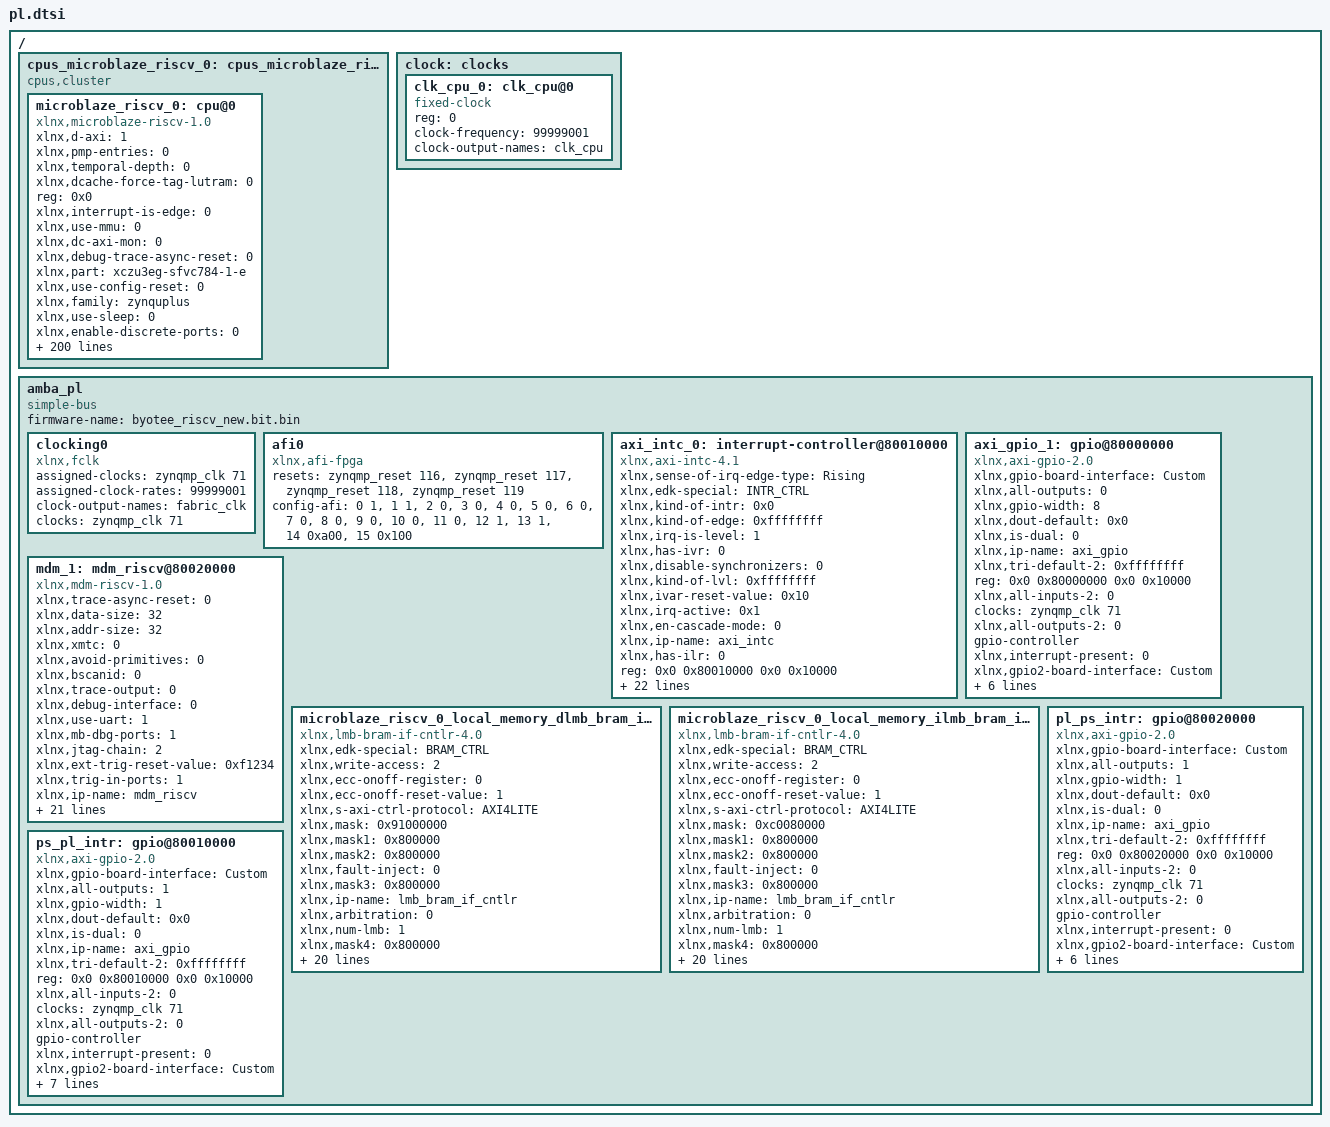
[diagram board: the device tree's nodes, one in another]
/ {
	cpus_microblaze_riscv_0: cpus_microblaze_riscv@0 {
		#cpu-mask-cells = <1>;
		compatible = "cpus,cluster";
		#address-cells = <1>;
		#size-cells = <0>;
		microblaze_riscv_0: cpu@0 {
			xlnx,d-axi = <1>;
			xlnx,pmp-entries = <0>;
			xlnx,temporal-depth = <0>;
			xlnx,dcache-force-tag-lutram = <0>;
			reg = <0x0>;
			xlnx,interrupt-is-edge = <0>;
			xlnx,use-mmu = <0>;
			xlnx,dc-axi-mon = <0>;
			xlnx,debug-trace-async-reset = <0>;
			xlnx,part = "xczu3eg-sfvc784-1-e";
			xlnx,use-config-reset = <0>;
			xlnx,family = "zynquplus";
			xlnx,use-sleep = <0>;
			xlnx,enable-discrete-ports = <0>;
			xlnx,d-lmb = <1>;
			xlnx,debug-interface = <0>;
			xlnx,use-ext-brk = <0>;
			xlnx,debug-enabled = <1>;
			xlnx,daddr-size = <32>;
			xlnx,use-extended-fsl-instr = <0>;
			xlnx,branch-target-cache-size = <0>;
			bus-handle = <&amba_pl>;
			xlnx,pmp-addr0 = <0x0>;
			xlnx,pmp-addr1 = <0x0>;
			xlnx,pmp-addr2 = <0x0>;
			xlnx,pmp-addr3 = <0x0>;
			xlnx,pmp-addr4 = <0x0>;
			xlnx,edk-special = "microblaze_riscv";
			xlnx,pmp-addr5 = <0x0>;
			xlnx,use-dcache = <0>;
			xlnx,use-muldiv = <0>;
			xlnx,pmp-addr6 = <0x0>;
			xlnx,use-axi-dp-ext-addr = <0>;
			xlnx,pmp-addr7 = <0x0>;
			xlnx,pmp-addr8 = <0x0>;
			xlnx,pmp-addr9 = <0x0>;
			xlnx,i-axi = <1>;
			xlnx,icache-streams = <0>;
			xlnx,num-sync-ff-dbg-clk = <1>;
			xlnx,icache-byte-size = <16384>;
			xlnx,pmp-addr10 = <0x0>;
			d-cache-size = <16384>;
			xlnx,pmp-addr11 = <0x0>;
			xlnx,pmp-addr12 = <0x0>;
			xlnx,pmp-addr13 = <0x0>;
			xlnx,pmp-addr14 = <0x0>;
			xlnx,pmp-addr15 = <0x0>;
			xlnx,avoid-primitives = <0>;
			xlnx,pmp-addr16 = <0x0>;
			xlnx,pmp-addr17 = <0x0>;
			xlnx,pmp-addr18 = <0x0>;
			xlnx,pdaddr-size = <32>;
			xlnx,pmp-addr19 = <0x0>;
			xlnx,pmp-addr20 = <0x0>;
			xlnx,pmp-addr21 = <0x0>;
			xlnx,i-lmb = <1>;
			xlnx,pmp-addr22 = <0x0>;
			xlnx,lmb-data-size = <32>;
			xlnx,lockstep-select = <0>;
			xlnx,pmp-addr23 = <0x0>;
			timebase-frequency = <99999001>;
			xlnx,pmp-addr24 = <0x0>;
			xlnx,dcache-data-width = <0>;
			xlnx,icache-force-tag-lutram = <0>;
			xlnx,pmp-addr25 = <0x0>;
			xlnx,pmp-addr26 = <0x0>;
			xlnx,use-branch-target-cache = <0>;
			xlnx,pmp-addr27 = <0x0>;
			xlnx,number-of-pc-brk = <1>;
			xlnx,pmp-addr28 = <0x0>;
			xlnx,imprecise-exceptions = <0>;
			xlnx,pmp-addr29 = <0x0>;
			xlnx,pmp-addr30 = <0x0>;
			xlnx,pmp-addr31 = <0x0>;
			xlnx,pmp-addr32 = <0x0>;
			model = "microblaze_riscv,1.0";
			xlnx,pmp-addr33 = <0x0>;
			xlnx,pmp-addr34 = <0x0>;
			xlnx,pmp-addr35 = <0x0>;
			xlnx,pmp-addr36 = <0x0>;
			d-cache-highaddr = <0xffffffff>;
			xlnx,optimization = <0>;
			xlnx,pmp-addr37 = <0x0>;
			xlnx,pmp-addr38 = <0x0>;
			xlnx,pmp-addr39 = <0x0>;
			xlnx,pmp-addr40 = <0x0>;
			xlnx,pmp-addr41 = <0x0>;
			xlnx,d-lmb-mon = <0>;
			xlnx,pmp-addr42 = <0x0>;
			xlnx,pmp-addr43 = <0x0>;
			xlnx,pmp-addr44 = <0x0>;
			xlnx,pmp-addr45 = <0x0>;
			xlnx,pmp-addr46 = <0x0>;
			xlnx,pmp-addr47 = <0x0>;
			xlnx,pmp-addr48 = <0x0>;
			xlnx,fault-tolerant = <0>;
			xlnx,pmp-addr49 = <0x0>;
			xlnx,pmp-addr50 = <0x0>;
			xlnx,pmp-addr51 = <0x0>;
			xlnx,pmp-enhancements = <0>;
			d-cache-line-size = <16>;
			xlnx,mmu-privileged-instr = <0>;
			xlnx,pmp-addr52 = <0x0>;
			clock-frequency = <99999001>;
			xlnx,pmp-addr53 = <0x0>;
			xlnx,pmp-addr54 = <0x0>;
			xlnx,pmp-addr55 = <0x0>;
			xlnx,i-lmb-protocol = <0>;
			xlnx,pmp-addr56 = <0x0>;
			xlnx,pmp-addr57 = <0x0>;
			xlnx,dp-axi-mon = <0>;
			xlnx,pmp-addr58 = <0x0>;
			xlnx,pmp-addr59 = <0x0>;
			xlnx,pmp-addr60 = <0x0>;
			xlnx,pmp-addr61 = <0x0>;
			xlnx,pmp-addr62 = <0x0>;
			xlnx,pmp-addr63 = <0x0>;
			xlnx,debug-external-trace = <0>;
			xlnx,addr-size = <32>;
			xlnx,debug-event-counters = <0>;
			xlnx,edk-iptype = "PROCESSOR";
			xlnx,debug-latency-counters = <0>;
			xlnx,interconnect = <2>;
			xlnx,edge-is-positive = <1>;
			xlnx,use-icache = <0>;
			xlnx,async-wakeup = <3>;
			xlnx,s-axi = <0>;
			xlnx,use-ext-nm-brk = <0>;
			xlnx,ic-axi-mon = <0>;
			xlnx,archid = <0x1>;
			xlnx,num-sync-ff-clk-irq = <1>;
			xlnx,freq = <99999001>;
			xlnx,lockstep-master = <0>;
			xlnx,pmp-cfg0 = <0x0>;
			xlnx,pmp-cfg1 = <0x0>;
			xlnx,iaddr-size = <32>;
			xlnx,interrupt-mon = <0>;
			xlnx,pmp-cfg2 = <0x0>;
			xlnx,number-of-wr-addr-brk = <0>;
			xlnx,pmp-cfg3 = <0x0>;
			xlnx,pmp-cfg4 = <0x0>;
			xlnx,use-interrupt = <1>;
			xlnx,pmp-cfg5 = <0x0>;
			xlnx,async-interrupt = <1>;
			xlnx,pc-width = <32>;
			xlnx,pmp-cfg6 = <0x0>;
			xlnx,icache-victims = <0>;
			xlnx,pmp-cfg7 = <0x0>;
			xlnx,pmp-cfg8 = <0x0>;
			xlnx,pmp-cfg9 = <0x0>;
			xlnx,use-bitman-a = <0>;
			xlnx,use-bitman-b = <0>;
			xlnx,use-bitman-c = <0>;
			xlnx,i-lmb-mon = <0>;
			xlnx,dcache-byte-size = <16384>;
			xlnx,data-size = <32>;
			compatible = "xlnx,microblaze-riscv-1.0" , "xlnx,microblaze_riscv";
			xlnx,pmp-debug-inhibit = <0x0>;
			xlnx,fsl-exception = <0>;
			xlnx,dcache-use-writeback = <0>;
			device_type = "cpu";
			xlnx,impid = <0x1>;
			xlnx,use-bitman-s = <0>;
			xlnx,base-vectors = <0x90080000>;
			xlnx,icache-line-len = <4>;
			xlnx,use-barrel = <1>;
			xlnx,misaligned-exceptions = <1>;
			xlnx,piaddr-size = <32>;
			xlnx,use-bitman = <0>;
			xlnx,dcache-line-len = <4>;
			xlnx,num-sync-ff-clk = <2>;
			xlnx,memory-ip-list = "psu_ddr_0_memory" , "psu_ddr_0_memory" , "psu_ocm_ram_0_memory" , "psu_ocm_ram_0_memory" , "psu_r5_1_btcm_global_memory" , "psu_r5_1_btcm_global_memory" , "psu_r5_1_atcm_global_memory" , "psu_r5_1_atcm_global_memory" , "psu_r5_0_btcm_global_memory" , "psu_r5_0_btcm_global_memory" , "psu_r5_0_atcm_global_memory" , "psu_r5_0_atcm_global_memory";
			xlnx,number-of-rd-addr-brk = <0>;
			xlnx,lockstep-slave = <0>;
			xlnx,use-counters = <1>;
			interrupt-handle = <&axi_intc_0>;
			xlnx,pmp-cfg10 = <0x0>;
			xlnx,pmp-cfg11 = <0x0>;
			xlnx,debug-profile-size = <0>;
			xlnx,pmp-cfg12 = <0x0>;
			xlnx,pmp-cfg13 = <0x0>;
			xlnx,pmp-cfg14 = <0x0>;
			xlnx,pmp-cfg15 = <0x0>;
			xlnx,debug-counter-width = <64>;
			xlnx,icache-data-width = <0>;
			xlnx,ip-name = "microblaze_riscv";
			xlnx,ip-axi-mon = <0>;
			xlnx,d-lmb-protocol = <0>;
			xlnx,trace = <0>;
			xlnx,ill-instr-exception = <2>;
			xlnx,debug-trace-size = <0>;
			xlnx,pmp-granularity = <2>;
			xlnx,num-sync-ff-dbg-trace-clk = <2>;
			xlnx,ecc-use-ce-exception = <0>;
			xlnx,num-sync-ff-clk-debug = <2>;
			xlnx,use-atomic = <0>;
			xlnx,g-template-list = <0>;
			xlnx,hartid = <0x0>;
			xlnx,use-fpu = <0>;
			xlnx,use-non-secure = <0>;
			d-cache-baseaddr = <0x80000000>;
			xlnx,use-compression = <0>;
			xlnx,instr-size = <32>;
			xlnx,fsl-links = <0>;
			xlnx,dcache-victims = <0>;
			xlnx,pmp-read-only = <0x0>;
		};
	};
	clock: clocks {
		#address-cells = <1>;
		#size-cells = <0>;
		clk_cpu_0: clk_cpu@0 {
			compatible = "fixed-clock";
			reg = <0>;
			clock-frequency = <99999001>;
			clock-output-names = "clk_cpu";
			#clock-cells = <0>;
		};
	};
	amba_pl: amba_pl {
		ranges;
		compatible = "simple-bus";
		#address-cells = <2>;
		#size-cells = <2>;
		firmware-name = "byotee_riscv_new.bit.bin";
		clocking0: clocking0 {
			compatible = "xlnx,fclk";
			status = "okay";
			assigned-clocks = <&zynqmp_clk 71>;
			assigned-clock-rates = <99999001>;
			#clock-cells = <0>;
			clock-output-names = "fabric_clk";
			clocks = <&zynqmp_clk 71>;
		};
		afi0: afi0 {
			status = "okay";
			compatible = "xlnx,afi-fpga";
			resets = <&zynqmp_reset 116>, <&zynqmp_reset 117>, <&zynqmp_reset 118>, <&zynqmp_reset 119>;
			config-afi = < 0 1>, <1 1>, <2 0>, <3 0>, <4 0>, <5 0>, <6 0>, <7 0>, <8 0>, <9 0>, <10 0>, <11 0>, <12 1>, <13 1>, <14 0xa00>, <15 0x100>;
		};
		axi_intc_0: interrupt-controller@80010000 {
			#interrupt-cells = <2>;
			xlnx,sense-of-irq-edge-type = "Rising";
			xlnx,edk-special = "INTR_CTRL";
			xlnx,kind-of-intr = <0x0>;
			xlnx,kind-of-edge = <0xffffffff>;
			xlnx,irq-is-level = <1>;
			xlnx,has-ivr = <0>;
			compatible = "xlnx,axi-intc-4.1" , "xlnx,xps-intc-1.00.a";
			xlnx,disable-synchronizers = <0>;
			xlnx,kind-of-lvl = <0xffffffff>;
			xlnx,ivar-reset-value = <0x10>;
			xlnx,irq-active = <0x1>;
			xlnx,en-cascade-mode = <0>;
			xlnx,ip-name = "axi_intc";
			xlnx,has-ilr = <0>;
			reg = <0x0 0x80010000 0x0 0x10000>;
			xlnx,addr-width = <0x20>;
			clocks = <&zynqmp_clk 71>;
			xlnx,s-axi-aclk-freq-mhz = <0x5f5dd19>;
			xlnx,num-sw-intr = <0>;
			xlnx,irq-connection = <0>;
			xlnx,num-intr-inputs = <0x1>;
			xlnx,has-sie = <0>;
			xlnx,enable-async = <0>;
			xlnx,has-cie = <0>;
			xlnx,num-sync-ff = <2>;
			xlnx,edk-iptype = "PERIPHERAL";
			xlnx,mb-clk-not-connected = <1>;
			xlnx,has-ipr = <1>;
			xlnx,sense-of-irq-level-type = "Active_High";
			xlnx,cascade-master = <0>;
			xlnx,processor-clk-freq-mhz = <100>;
			status = "okay";
			xlnx,is-fast = <0x0>;
			clock-names = "s_axi_aclk";
			xlnx,has-fast = <0>;
			xlnx,ivar-rst-val = <0x10>;
			interrupt-controller;
			xlnx,async-intr = <0xfffffffe>;
			xlnx,name = "axi_intc_0";
		};
		axi_gpio_1: gpio@80000000 {
			xlnx,gpio-board-interface = "Custom";
			compatible = "xlnx,axi-gpio-2.0" , "xlnx,xps-gpio-1.00.a";
			xlnx,all-outputs = <0>;
			#gpio-cells = <2>;
			xlnx,gpio-width = <8>;
			xlnx,dout-default = <0x0>;
			xlnx,is-dual = <0>;
			xlnx,ip-name = "axi_gpio";
			xlnx,tri-default-2 = <0xffffffff>;
			reg = <0x0 0x80000000 0x0 0x10000>;
			xlnx,all-inputs-2 = <0>;
			clocks = <&zynqmp_clk 71>;
			xlnx,all-outputs-2 = <0>;
			gpio-controller;
			xlnx,interrupt-present = <0>;
			xlnx,gpio2-board-interface = "Custom";
			xlnx,edk-iptype = "PERIPHERAL";
			xlnx,dout-default-2 = <0x0>;
			status = "okay";
			xlnx,gpio2-width = <32>;
			clock-names = "s_axi_aclk";
			xlnx,tri-default = <0xffffffff>;
			xlnx,name = "axi_gpio_1";
			xlnx,all-inputs = <0>;
		};
		mdm_1: mdm_riscv@80020000 {
			xlnx,trace-async-reset = <0>;
			compatible = "xlnx,mdm-riscv-1.0";
			xlnx,data-size = <32>;
			xlnx,addr-size = <32>;
			xlnx,xmtc = <0>;
			xlnx,avoid-primitives = <0>;
			xlnx,bscanid = <0>;
			xlnx,trace-output = <0>;
			xlnx,debug-interface = <0>;
			xlnx,use-uart = <1>;
			xlnx,mb-dbg-ports = <1>;
			xlnx,jtag-chain = <2>;
			xlnx,ext-trig-reset-value = <0xf1234>;
			xlnx,trig-in-ports = <1>;
			xlnx,ip-name = "mdm_riscv";
			xlnx,brk = <0>;
			xlnx,dbg-reg-access = <0>;
			xlnx,use-bscan-switch = <0>;
			reg = <0x0 0x80020000 0x0 0x10000>;
			clocks = <&zynqmp_clk 71>, <&zynqmp_clk 71>;
			xlnx,use-bscan = <0>;
			xlnx,trace-id = <110>;
			xlnx,lmb-protocol = <0>;
			xlnx,dtm-idcode = <147>;
			xlnx,trace-data-width = <32>;
			xlnx,edk-iptype = "PERIPHERAL";
			xlnx,use-jtag-bscan = <1>;
			xlnx,interconnect = <2>;
			xlnx,use-cross-trigger = <0>;
			xlnx,trace-protocol = <1>;
			status = "okay";
			clock-names = "M_AXI_ACLK" , "S_AXI_ACLK";
			xlnx,use-config-reset = <0>;
			xlnx,trig-out-ports = <1>;
			xlnx,device = "xczu3eg";
			xlnx,dbg-mem-access = <1>;
			xlnx,trace-clk-out-phase = <90>;
			xlnx,name = "mdm_1";
		};
		microblaze_riscv_0_local_memory_dlmb_bram_if_cntlr: lmb_bram_if_cntlr@0 {
			xlnx,edk-special = "BRAM_CTRL";
			xlnx,write-access = <2>;
			compatible = "xlnx,lmb-bram-if-cntlr-4.0" , "xlnx,axi-bram-ctrl";
			xlnx,ecc-onoff-register = <0>;
			xlnx,ecc-onoff-reset-value = <1>;
			xlnx,s-axi-ctrl-protocol = "AXI4LITE";
			xlnx,mask = <0x91000000>;
			xlnx,mask1 = <0x800000>;
			xlnx,mask2 = <0x800000>;
			xlnx,fault-inject = <0>;
			xlnx,mask3 = <0x800000>;
			xlnx,ip-name = "lmb_bram_if_cntlr";
			xlnx,arbitration = <0>;
			xlnx,num-lmb = <1>;
			xlnx,mask4 = <0x800000>;
			reg = <0x0 0x90000000 0x0 0x40000>;
			xlnx,s-axi-ctrl-addr-width = <32>;
			xlnx,mask5 = <0x800000>;
			xlnx,ecc-status-registers = <0>;
			xlnx,mask6 = <0x800000>;
			xlnx,lmb-protocol = <0>;
			xlnx,ce-counter-width = <0>;
			xlnx,mask7 = <0x800000>;
			xlnx,ecc = <0>;
			xlnx,edk-iptype = "PERIPHERAL";
			xlnx,lmb-dwidth = <32>;
			xlnx,interconnect = <0>;
			xlnx,ce-failing-registers = <0>;
			xlnx,ue-failing-registers = <0>;
			status = "okay";
			xlnx,data-width = <32>;
			xlnx,s-axi-ctrl-data-width = <32>;
			xlnx,bram-awidth = <32>;
			xlnx,lmb-awidth = <32>;
			xlnx,name = "microblaze_riscv_0_local_memory_dlmb_bram_if_cntlr";
		};
		microblaze_riscv_0_local_memory_ilmb_bram_if_cntlr: lmb_bram_if_cntlr@1 {
			xlnx,edk-special = "BRAM_CTRL";
			xlnx,write-access = <2>;
			compatible = "xlnx,lmb-bram-if-cntlr-4.0" , "xlnx,axi-bram-ctrl";
			xlnx,ecc-onoff-register = <0>;
			xlnx,ecc-onoff-reset-value = <1>;
			xlnx,s-axi-ctrl-protocol = "AXI4LITE";
			xlnx,mask = <0xc0080000>;
			xlnx,mask1 = <0x800000>;
			xlnx,mask2 = <0x800000>;
			xlnx,fault-inject = <0>;
			xlnx,mask3 = <0x800000>;
			xlnx,ip-name = "lmb_bram_if_cntlr";
			xlnx,arbitration = <0>;
			xlnx,num-lmb = <1>;
			xlnx,mask4 = <0x800000>;
			reg = <0x0 0x90080000 0x0 0x40000>;
			xlnx,s-axi-ctrl-addr-width = <32>;
			xlnx,mask5 = <0x800000>;
			xlnx,ecc-status-registers = <0>;
			xlnx,mask6 = <0x800000>;
			xlnx,lmb-protocol = <0>;
			xlnx,ce-counter-width = <0>;
			xlnx,mask7 = <0x800000>;
			xlnx,ecc = <0>;
			xlnx,edk-iptype = "PERIPHERAL";
			xlnx,lmb-dwidth = <32>;
			xlnx,interconnect = <0>;
			xlnx,ce-failing-registers = <0>;
			xlnx,ue-failing-registers = <0>;
			status = "okay";
			xlnx,data-width = <32>;
			xlnx,s-axi-ctrl-data-width = <32>;
			xlnx,bram-awidth = <32>;
			xlnx,lmb-awidth = <32>;
			xlnx,name = "microblaze_riscv_0_local_memory_ilmb_bram_if_cntlr";
		};
		pl_ps_intr: gpio@80020000 {
			xlnx,gpio-board-interface = "Custom";
			compatible = "xlnx,axi-gpio-2.0" , "xlnx,xps-gpio-1.00.a";
			xlnx,all-outputs = <1>;
			#gpio-cells = <2>;
			xlnx,gpio-width = <1>;
			xlnx,dout-default = <0x0>;
			xlnx,is-dual = <0>;
			xlnx,ip-name = "axi_gpio";
			xlnx,tri-default-2 = <0xffffffff>;
			reg = <0x0 0x80020000 0x0 0x10000>;
			xlnx,all-inputs-2 = <0>;
			clocks = <&zynqmp_clk 71>;
			xlnx,all-outputs-2 = <0>;
			gpio-controller;
			xlnx,interrupt-present = <0>;
			xlnx,gpio2-board-interface = "Custom";
			xlnx,edk-iptype = "PERIPHERAL";
			xlnx,dout-default-2 = <0x0>;
			status = "okay";
			xlnx,gpio2-width = <32>;
			clock-names = "s_axi_aclk";
			xlnx,tri-default = <0xffffffff>;
			xlnx,name = "pl_ps_intr";
			xlnx,all-inputs = <0>;
		};
		ps_pl_intr: gpio@80010000 {
			xlnx,gpio-board-interface = "Custom";
			compatible = "xlnx,axi-gpio-2.0" , "xlnx,xps-gpio-1.00.a";
			xlnx,all-outputs = <1>;
			#gpio-cells = <2>;
			xlnx,gpio-width = <1>;
			xlnx,dout-default = <0x0>;
			xlnx,is-dual = <0>;
			xlnx,ip-name = "axi_gpio";
			xlnx,tri-default-2 = <0xffffffff>;
			reg = <0x0 0x80010000 0x0 0x10000>;
			xlnx,all-inputs-2 = <0>;
			clocks = <&zynqmp_clk 71>;
			xlnx,all-outputs-2 = <0>;
			gpio-controller;
			xlnx,interrupt-present = <0>;
			xlnx,gpio2-board-interface = "Custom";
			xlnx,edk-iptype = "PERIPHERAL";
			xlnx,dout-default-2 = <0x0>;
			status = "okay";
			xlnx,gpio2-width = <32>;
			clock-names = "s_axi_aclk";
			xlnx,use-board-flow;
			xlnx,tri-default = <0xffffffff>;
			xlnx,name = "ps_pl_intr";
			xlnx,all-inputs = <0>;
		};
	};
};
